# apollo2 register map
Vendor: Ambiq Micro; Series: Apollo; File version: 1.0
CPU: CM4 r1p0, little endian, MPU, FPU, 3 interrupt priority bits
Registers are 32-bit, read-write, reset 0x0 unless marked. A register's access mark holds for its fields unless they carry their own. Offsets are from the block's base; [hi:lo] are bit positions.

## CACHECTRL — Flash Cache Controller
Base 0x40018000
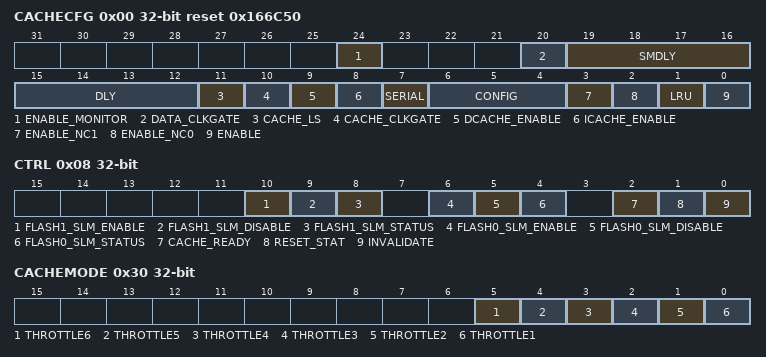
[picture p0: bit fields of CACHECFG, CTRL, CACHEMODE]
0x00 CACHECFG reset 0x166C50 — Flash Cache Control Register
  [24] ENABLE_MONITOR — Enable Cache Monitoring Stats. Only enable this for debug/performance analysis since it will consume additional power. See IMON/DMON registers for data.
  [20] DATA_CLKGATE — Enable clock gating of entire cache data array subsystem. This should be enabled for normal operation.
  [19:16] SMDLY — Unused. Should be left at default value.
  [15:12] DLY — Unused. Should be left at default value.
  [11] CACHE_LS — Enable LS (light sleep) of cache RAMs. This should not be enabled for normal operation. When this bit is set, the cache's RAMS will be put into light sleep mode while inactive. NOTE: if the cache is actively used, this may have an adverse affect on power since entering/exiting LS mode may consume more power than would be saved.
  [10] CACHE_CLKGATE — Enable clock gating of individual cache RAMs. This bit should be enabled for normal operation for lowest power consumption.
  [9] DCACHE_ENABLE — Enable Flash Data Caching. When set to 1, all instruction accesses to flash will be cached.
  [8] ICACHE_ENABLE — Enable Flash Instruction Caching. When set to 1, all instruction accesses to flash will be cached.
  [7] SERIAL — Bitfield should always be programmed to 0.
  [6:4] CONFIG — Sets the cache configuration. Only a single configuration of 0x5 is valid.
    5=W2_128B_512E (Two-way set associative, 128-bit linesize, 512 entries (8 SRAMs active) value.)
  [3] ENABLE_NC1 — Enable Non-cacheable region 1. See the NCR1 registers to set the region boundaries and size.
  [2] ENABLE_NC0 — Enable Non-cacheable region 0. See the NCR0 registers to set the region boundaries and size.
  [1] LRU — Sets the cache replacement policy. 0=LRR (least recently replaced), 1=LRU (least recently used). LRR minimizes writes to the TAG SRAM and is recommended.
  [0] ENABLE — Enables the main flash cache controller logic and enables power to the cache RAMs. Instruction and Data caching need to be enabled independently using the ICACHE_ENABLE and DCACHE_ENABLE bits.
0x04 FLASHCFG reset 0x1 — Flash Control Register
  [2:0] RD_WAIT — Sets read waitstates for flash accesses (in clock cycles). This should be left at the default value for normal flash operation.
0x08 CTRL — Cache Control
  [10] FLASH1_SLM_ENABLE — Enable Flash Sleep Mode. After writing this bit, the flash instance 1 will enter a low-power mode until the CPU writes the SLM_DISABLE bit or a flash access occurs. Wake from SLM requires ~5us, so this should only be set if the flash will not be accessed for reasonably long time.
  [9] FLASH1_SLM_DISABLE — Disable Flash Sleep Mode. Allows CPU to manually disable SLM mode. Performing a flash read will also wake the array.
  [8] FLASH1_SLM_STATUS — Flash Sleep Mode Status. When 1, flash instance 1 is asleep.
  [6] FLASH0_SLM_ENABLE — Enable Flash Sleep Mode. After writing this bit, the flash instance 0 will enter a low-power mode until the CPU writes the SLM_DISABLE bit or a flash access occurs. Wake from SLM requires ~5us, so this should only be set if the flash will not be accessed for reasonably long time.
  [5] FLASH0_SLM_DISABLE — Disable Flash Sleep Mode. Allows CPU to manually disable SLM mode. Performing a flash read will also wake the array.
  [4] FLASH0_SLM_STATUS — Flash Sleep Mode Status. When 1, flash instance 0 is asleep.
  [2] CACHE_READY — Cache Ready Status. A value of 1 indicates the cache is enabled and not processing an invalidate operation.
  [1] RESET_STAT — Writing a 1 to this bitfield will reset the cache monitor statistics (DMON0-3, IMON0-3). Statistic gathering can be paused/stopped by disabling the MONITOR_ENABLE bit in CACHECFG, which will maintain the count values until the stats are reset by writing this bitfield.
    1=CLEAR (Clear Cache Stats value.)
  [0] INVALIDATE — Writing a 1 to this bitfield invalidates the flash cache contents.
    1=GO (Initiate a programming operation to flash info. value.)
0x10 NCR0START — Flash Cache Noncachable Region 0 Start Address.
  [19:4] ADDR — Start address for non-cacheable region 0. The physical address of the start of this region should be programmed to this register and must be aligned to a 16-byte boundary (thus the lower 4 address bits are unused).
0x14 NCR0END — Flash Cache Noncachable Region 0 End
  [19:4] ADDR — End address for non-cacheable region 0. The physical address of the end of this region should be programmed to this register and must be aligned to a 16-byte boundary (thus the lower 4 address bits are unused).
0x18 NCR1START — Flash Cache Noncachable Region 1 Start
  [19:4] ADDR — Start address for non-cacheable region 1. The physical address of the start of this region should be programmed to this register and must be aligned to a 16-byte boundary (thus the lower 4 address bits are unused).
0x1C NCR1END — Flash Cache Noncachable Region 1 End
  [19:4] ADDR — End address for non-cacheable region 1. The physical address of the end of this region should be programmed to this register and must be aligned to a 16-byte boundary (thus the lower 4 address bits are unused).
0x30 CACHEMODE — Flash Cache Mode Register. Used to trim performance/power.
  [5] THROTTLE6 — Disallow Simultaneous Data RAM reads (from 2 line hits on each bus). Value should be left at zero for optimal performance.
  [4] THROTTLE5 — Disallow Data RAM reads (from line hits) during lookup read ops. Value should be left at zero for optimal performance.
  [3] THROTTLE4 — Disallow Data RAM reads (from line hits) on tag RAM fill cycles. Value should be left at zero for optimal performance.
  [2] THROTTLE3 — Disallow cache data RAM writes on data RAM read cycles. Value should be left at zero for optimal performance.
  [1] THROTTLE2 — Disallow cache data RAM writes on tag RAM read cycles. Value should be left at zero for optimal performance.
  [0] THROTTLE1 — Disallow cache data RAM writes on tag RAM fill cycles. Value should be left at zero for optimal performance.
0x40 DMON0 — Data Cache Total Accesses
  [31:0] DACCESS_COUNT — Total accesses to data cache
0x44 DMON1 — Data Cache Tag Lookups
  [31:0] DLOOKUP_COUNT — Total tag lookups from data cache
0x48 DMON2 — Data Cache Hits
  [31:0] DHIT_COUNT — Cache hits from lookup operations
0x4C DMON3 — Data Cache Line Hits
  [31:0] DLINE_COUNT — Cache hits from line cache
0x50 IMON0 — Instruction Cache Total Accesses
  [31:0] IACCESS_COUNT — Total accesses to Instruction cache
0x54 IMON1 — Instruction Cache Tag Lookups
  [31:0] ILOOKUP_COUNT — Total tag lookups from Instruction cache
0x58 IMON2 — Instruction Cache Hits
  [31:0] IHIT_COUNT — Cache hits from lookup operations
0x5C IMON3 — Instruction Cache Line Hits
  [31:0] ILINE_COUNT — Cache hits from line cache
